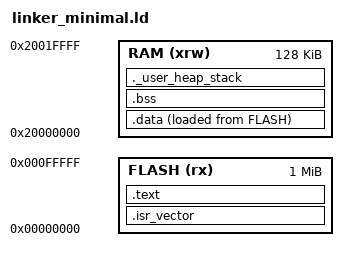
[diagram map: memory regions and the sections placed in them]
/* Entry Point */
ENTRY(Reset_Handler)

/* Specify the memory areas */
MEMORY
{
  FLASH (rx)      : ORIGIN = 0x00000000, LENGTH = 1024K
  RAM (xrw)       : ORIGIN = 0x20000000, LENGTH = 128K
}

/* Define output sections */
SECTIONS
{
  /* The startup code goes first into FLASH */
  .isr_vector :
  {
    . = ALIGN(4);
    KEEP(*(.isr_vector)) /* Startup code */
    . = ALIGN(4);
  } >FLASH

  /* The program code and other data goes into FLASH */
  .text :
  {
    . = ALIGN(4);
    *(.text)           /* .text sections (code) */
    *(.text*)          /* .text* sections (code) */
    *(.rodata)         /* .rodata sections (constants, strings, etc.) */
    *(.rodata*)        /* .rodata* sections (constants, strings, etc.) */
    *(.glue_7)         /* glue arm to thumb code */
    *(.glue_7t)        /* glue thumb to arm code */
    KEEP (*(.init))
    KEEP (*(.fini))
    . = ALIGN(4);
    _etext = .;        /* define a global symbols at end of code */
  } >FLASH

  /* Used by the startup to initialize data */
  _sidata = LOADADDR(.data);

  /* Initialized data sections goes into RAM, load LMA copy after code */
  .data :
  {
    . = ALIGN(4);
    _sdata = .;        /* create a global symbol at data start */
    *(.data)           /* .data sections */
    *(.data*)          /* .data* sections */
    . = ALIGN(4);
    _edata = .;        /* define a global symbol at data end */
  } >RAM AT> FLASH

  /* Uninitialized data section */
  .bss :
  {
    . = ALIGN(4);
    _sbss = .;         /* define a global symbol at bss start */
    *(.bss)
    *(.bss*)
    *(COMMON)
    . = ALIGN(4);
    _ebss = .;         /* define a global symbol at bss end */
  } >RAM

  /* User_heap_stack section, used to check that there is enough RAM left */
  ._user_heap_stack :
  {
    . = ALIGN(8);
    PROVIDE ( end = . );
    PROVIDE ( _end = . );
    . = . + 0x1000;    /* 4KB of heap space */
    . = . + 0x1000;    /* 4KB of stack space */
    . = ALIGN(8);
  } >RAM

  /* Remove information from the standard libraries */
  /DISCARD/ :
  {
    libc.a ( * )
    libm.a ( * )
    libgcc.a ( * )
  }
} 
